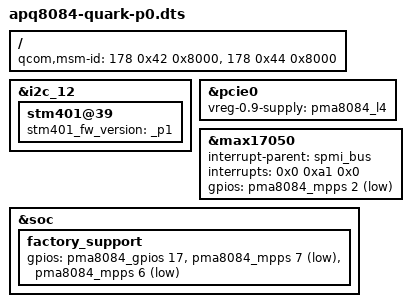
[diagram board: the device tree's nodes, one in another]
/* Copyright (c) 2014 Motorola Mobility LLC
 *
 * This program is free software; you can redistribute it and/or modify
 * it under the terms of the GNU General Public License version 2 and
 * only version 2 as published by the Free Software Foundation.
 *
 * This program is distributed in the hope that it will be useful,
 * but WITHOUT ANY WARRANTY; without even the implied warranty of
 * MERCHANTABILITY or FITNESS FOR A PARTICULAR PURPOSE.  See the
 * GNU General Public License for more details.
 */

/dts-v1/;

#include "apq8084-moto-reserve.dtsi"
#include "apq8084.dtsi"
#include "apq8084-quark.dtsi"

/ {
	qcom,msm-id = <178 0x42 0x8000>,
		  <178 0x44 0x8000>; /* MAXX */

	/delete-node/ cycapsense_prog;
};

&i2c_12 {
	stm401@39 {
		stm401_fw_version = "_p1";
	};
};

&pcie0 {
	vreg-0.9-supply = <&pma8084_l4>;
};

&max17050 {
	interrupt-parent = <&spmi_bus>;
	interrupts = <0x0 0xa1 0x0>;    /* PMA8084 MPP 2 */
	gpios = <&pma8084_mpps 2 0x1>;  /* GPIOF_DIR_IN */
};

&soc {
	factory_support {
		gpios = <&pma8084_gpios 17 0x0>, /* GPIOF_OUT_INIT_LOW */
			<&pma8084_mpps 7 0x1>, /* GPIOF_IN */
			<&pma8084_mpps 6 0x1>; /* GPIOF_IN */
	};
};
